# MKW41Z4 register map
Vendor: Freescale Semiconductor, Inc.; Series: Kinetis_W; File version: 1.6
CPU: CM0PLUS r0p0, little endian, no MPU, no FPU, VTOR, 2 interrupt priority bits
Registers are 16-bit, read-write, no defined reset value unless marked. A register's access mark holds for its fields unless they carry their own. Offsets are from the block's base; [hi:lo] are bit positions; {n}, {i} and the like mark numbered series; 'fields as' and 'values as' point back to an identical list.

## LTC0 — LTC
Base 0x40058000
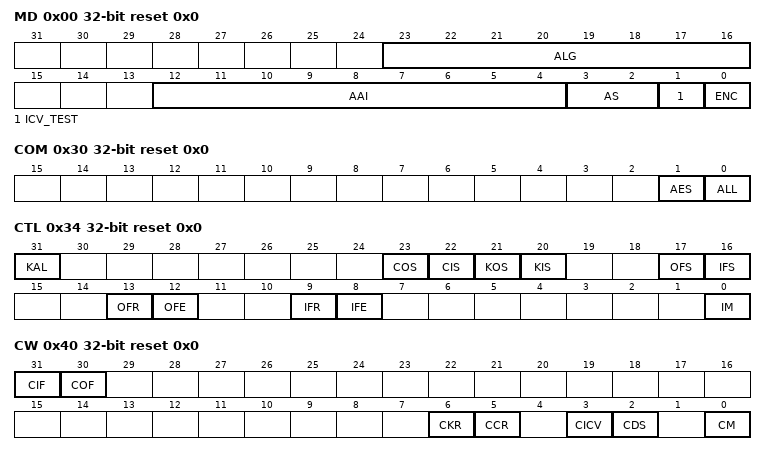
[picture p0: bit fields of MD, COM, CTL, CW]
0x00 MD 32-bit reset 0x0 — Mode Register
  [23:16] ALG — Algorithm
    16=AES
  [12:4] AAI — Additional Algorithm information
  [3:2] AS — Algorithm State
    0=Update; 1=Initialize; 2=Finalize; 3=Initialize/Finalize
  [1] ICV_TEST — ICV Checking / Test AES fault detection.
  [0] ENC — Encrypt/Decrypt.
    0=Decrypt; 1=Encrypt
0x08 KS 32-bit reset 0x10 — Key Size Register
  [4:0] KS wo — Key Size
0x10 DS 32-bit reset 0x0 — Data Size Register
  [11:0] DS — Data Size
0x18 ICVS 32-bit reset 0x0 — ICV Size Register
  [4:0] ICVS — ICV Size, in Bytes
0x30 COM 32-bit reset 0x0 — Command Register
  [1] AES wo — Reset AESA
    0=Do Not Reset; 1=Reset AES Accelerator
  [0] ALL wo — Reset All Internal Logic
    0=Do Not Reset; 1=Reset all CHAs in use by this CCB
0x34 CTL 32-bit reset 0x0 — Control Register
  [31] KAL — Key Register Access Lock
    0=Key Register is readable; 1=Key Register is not readable
  [23] COS — Context Register Output Byte Swap
    0=Do Not Byte Swap Data; 1=Byte Swap Data
  [22] CIS — Context Register Input Byte Swap
    0=Do Not Byte Swap Data; 1=Byte Swap Data
  [21] KOS — Key Register Output Byte Swap
    0=Do Not Byte Swap Data; 1=Byte Swap Data
  [20] KIS — Key Register Input Byte Swap
    0=Do Not Byte Swap Data; 1=Byte Swap Data
  [17] OFS — Output FIFO Byte Swap
    0=Do Not Byte Swap Data; 1=Byte Swap Data
  [16] IFS — Input FIFO Byte Swap
    0=Do Not Byte Swap Data; 1=Byte Swap Data
  [13] OFR — Output FIFO DMA Request Size
    0=DMA request size is 1 entry; 1=DMA request size is 4 entries
  [12] OFE — Output FIFO DMA Enable
    0=DMA Request and Done signals disabled for the Output FIFO; 1=DMA Request and Done signals enabled for the Output FIFO
  [9] IFR — Input FIFO DMA Request Size
    values as OFR
  [8] IFE — Input FIFO DMA Enable
    0=DMA Request and Done signals disabled for the Input FIFO; 1=DMA Request and Done signals enabled for the Input FIFO
  [0] IM — Interrupt Mask
    0=Interrupt not masked; 1=Interrupt masked
0x40 CW 32-bit reset 0x0 — Clear Written Register
  [31] CIF wo — Clear Input FIFO
  [30] COF wo — Clear Output FIFO
  [6] CKR wo — Clear the Key Register
  [5] CCR wo — Clear the Context Register
  [3] CICV wo — Clear the ICV Size Register
  [2] CDS wo — Clear the Data Size Register
  [0] CM wo — Clear the Mode Register
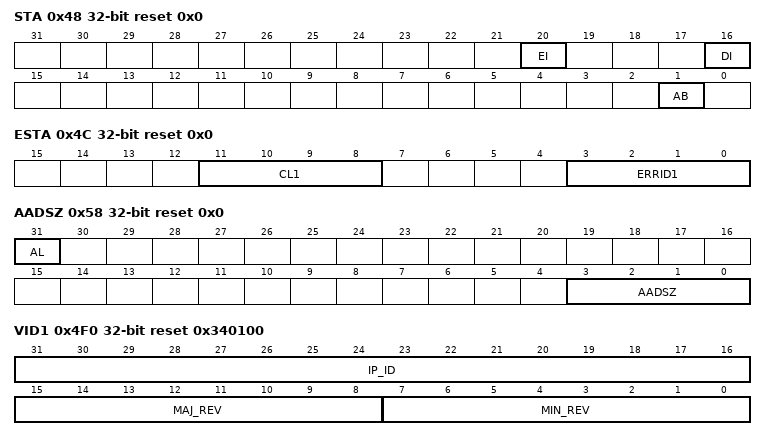
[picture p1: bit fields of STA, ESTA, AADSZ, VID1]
0x48 STA 32-bit reset 0x0 — Status Register
  [20] EI ro — Error Interrupt
    0=Not Error; 1=Error Interrupt
  [16] DI — Done Interrupt
  [1] AB ro — AESA Busy
    0=AESA Idle; 1=AESA Busy
0x4C ESTA 32-bit ro reset 0x0 — Error Status Register
  [11:8] CL1 — algorithms
    0=General Error; 1=AES
  [3:0] ERRID1 — Error ID 1
    1=Mode Error; 2=Data Size Error; 3=Key Size Error; 6=Data Arrived out of Sequence Error; 10=ICV Check Failed; 11=Internal Hardware Failure; 12=CCM AAD Size Error (either 1. AAD flag in B0 =1 and no AAD type provided, 2. AAD flag in B0 = 0 and AAD povided, or 3. AAD flag in B0 =1 and not enough AAD provided - expecting more based on AAD size.); 15=Invalid Crypto Engine Selected
0x58 AADSZ 32-bit reset 0x0 — AAD Size Register
  [31] AL — AAD Last
  [3:0] AADSZ — AAD size in Bytes, mod 16
{0x100+4i} CTX_{i} 32-bit reset 0x0 (i=0..13) — Context Register
  [31:0] CTX
{0x200+4i} KEY_{i} 32-bit reset 0x0 (i=0..3) — Key Registers
  [31:0] KEY
0x4F0 VID1 32-bit ro reset 0x340100 — Version ID Register
  [31:16] IP_ID — ID(0x0034).
  [15:8] MAJ_REV — Major revision number.
  [7:0] MIN_REV — Minor revision number.
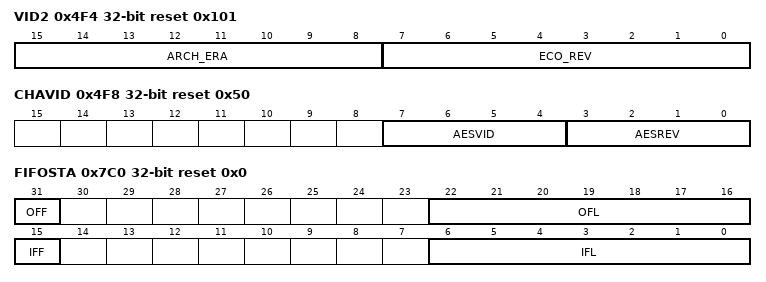
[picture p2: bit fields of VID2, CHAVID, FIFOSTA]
0x4F4 VID2 32-bit ro reset 0x101 — Version ID 2 Register
  [15:8] ARCH_ERA — Architectural ERA.
  [7:0] ECO_REV — ECO revision number.
0x4F8 CHAVID 32-bit ro reset 0x50 — CHA Version ID Register
  [7:4] AESVID — AES Version ID
  [3:0] AESREV — AES Revision Number
0x7C0 FIFOSTA 32-bit ro reset 0x0 — FIFO Status Register
  [31] OFF — Output FIFO Full
  [22:16] OFL — Output FIFO Level
  [15] IFF — Input FIFO Full
  [6:0] IFL — Input FIFO Level
0x7E0 IFIFO 32-bit wo reset 0x0 — Input Data FIFO
0x7F0 OFIFO 32-bit ro reset 0x0 — Output Data FIFO
  [31:0] OFIFO — Output FIFO
